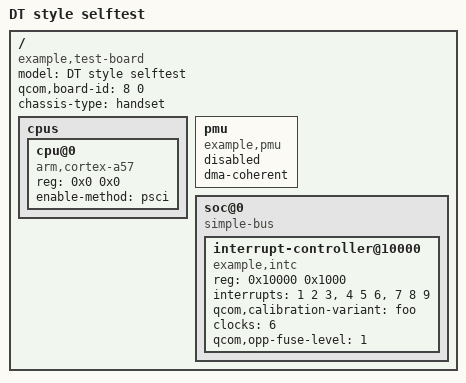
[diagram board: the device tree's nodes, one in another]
// SPDX-License-Identifier: GPL-2.0-only OR BSD-2-Clause
/*
 * Test fixture: Incorrect property order
 */

/dts-v1/;

/ {
	compatible = "example,test-board", "example,test-soc";
	model = "DT style selftest";
	qcom,board-id = <8 0>;
	chassis-type = "handset";

	cpus {
		#address-cells = <1>;
		#size-cells = <0>;

		cpu@0 {
			reg = <0x0 0x0>;
			compatible = "arm,cortex-a57";
			device_type = "cpu";
			enable-method = "psci";
		};
	};

	pmu {
		compatible = "example,pmu";

		status = "disabled";
		dma-coherent;
	};

	soc@0 {
		ranges = <0 0 0 0xc0000000>;
		compatible = "simple-bus";

		#address-cells = <1>;
		#size-cells = <1>;

		interrupt-controller@10000 {
			reg = <0x10000 0x1000>;
			interrupts = <1 2 3>,
				     <4 5 6>,
				     <7 8 9>;
			compatible = "example,intc";
			qcom,calibration-variant = "foo";
			clocks = <6>;
			qcom,opp-fuse-level = <1>;
		};
	};
};

/  {
	compatible = "example,test-board", "example,test-soc";
	model = "DT style selftest";
};

/{
	compatible = "example,test-board", "example,test-soc";
	model = "DT style selftest";
};
